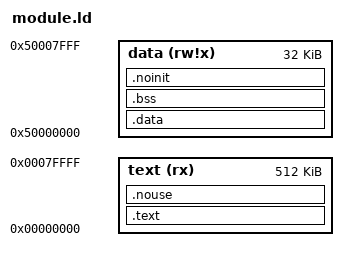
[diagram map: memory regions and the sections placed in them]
MEMORY
{
  text   (rx)   : ORIGIN = 0x00000000, LENGTH = 512K
  data   (rw!x) : ORIGIN = 0x50000000, LENGTH = 32K
}
SECTIONS
{
  .text :
  {
    *(.progmem*)
    . = ALIGN(4);
    *(.text)
    . = ALIGN(4);
    *(.text.*)
    . = ALIGN(4);
    *(.module)
    . = ALIGN(4);
    *(.rodata)
    *(.rodata.*)    
     _etext = . ;
  }  > text
  .nouse  : AT (ADDR (.text) + SIZEOF (.text))
  {
    *(.vectors)
     __ctors_start = . ;
     *(.ctors)
     __ctors_end = . ;
     __dtors_start = . ;
     *(.dtors)
     __dtors_end = . ;
    *(.progmem.gcc*)
    *(.init0)  /* Start here after reset.  */
    *(.init1)
    *(.init2)  /* Clear __zero_reg__, set up stack pointer.  */
    *(.init3)
    *(.init4)  /* Initialize data and BSS.  */
    *(.init5)
    *(.init6)  /* C++ constructors.  */
    *(.init7)
    *(.init8)
    *(.init9)  /* Call main().  */
    *(.fini9)  /* _exit() starts here.  */
    *(.fini8)
    *(.fini7)
    *(.fini6)  /* C++ destructors.  */
    *(.fini5)
    *(.fini4)
    *(.fini3)
    *(.fini2)
    *(.fini1)
    *(.fini0)  /* Infinite loop after program termination.  */
  }  > text
  .data	  : AT (ADDR (.nouse) + SIZEOF (.nouse))
  {
     PROVIDE (__data_start = .) ;
    *(.data)
    *(.gnu.linkonce.d*)
    . = ALIGN(2);
     _edata = . ;
     PROVIDE (__data_end = .) ;
  }  > data
  .bss  SIZEOF(.data) + ADDR(.data) :
  {
     PROVIDE (__bss_start = .) ;
    *(.bss)
    *(COMMON)
     PROVIDE (__bss_end = .) ;
  }  > data
   __data_load_start = LOADADDR(.data);
   __data_load_end = __data_load_start + SIZEOF(.data);
  /* Global data not cleared after reset.  */
  .noinit  SIZEOF(.bss) + ADDR(.bss) :
  {
     PROVIDE (__noinit_start = .) ;
    *(.noinit*)
     PROVIDE (__noinit_end = .) ;
     _end = . ;
     PROVIDE (__heap_start = .) ;
  }  > data
}
